VERSION "Powertrain_CAN_v1.0"

NS_ :

BS_:

BU_: SIL_TEST_CTRL ENGINE_CTRL TRANSMISSION_CTRL CHASSIS_GW DOMAIN_GW_ROUTER Vector__XXX

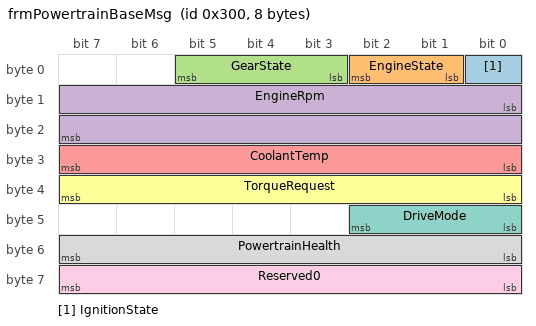
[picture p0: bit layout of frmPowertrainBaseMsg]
BO_ 768 frmPowertrainBaseMsg: 8 ENGINE_CTRL
 SG_ IgnitionState   : 0|1@1+ (1,0) [0|1] "" SIL_TEST_CTRL,CHASSIS_GW
 SG_ EngineState     : 1|2@1+ (1,0) [0|3] "" SIL_TEST_CTRL,CHASSIS_GW
 SG_ GearState       : 3|3@1+ (1,0) [0|7] "" SIL_TEST_CTRL,CHASSIS_GW
 SG_ EngineRpm       : 8|16@1+ (1,0) [0|65535] "rpm" CHASSIS_GW,DOMAIN_GW_ROUTER
 SG_ CoolantTemp     : 24|8@1+ (1,0) [0|255] "degC" DOMAIN_GW_ROUTER
 SG_ TorqueRequest   : 32|8@1+ (1,0) [0|255] "Nm" DOMAIN_GW_ROUTER
 SG_ DriveMode       : 40|3@1+ (1,0) [0|7] "" DOMAIN_GW_ROUTER
 SG_ PowertrainHealth: 48|8@1+ (1,0) [0|255] "" DOMAIN_GW_ROUTER
 SG_ Reserved0       : 56|8@1+ (1,0) [0|0] "" Vector__XXX

CM_ BO_ 768 "Comm_101 baseline powertrain aggregate message (Req_101~Req_102).";

BA_DEF_ BO_ "GenMsgCycleTime" INT 0 10000;
BA_DEF_DEF_ "GenMsgCycleTime" 0;
BA_ "GenMsgCycleTime" BO_ 768 100;

  0 "Off"
  1 "On" ;

  0 "Off"
  1 "Starting"
  2 "Running"
  3 "Fault" ;

  0 "Normal"
  1 "Eco"
  2 "Sport"
  3 "Snow"
  4 "Comfort"
  5 "Custom"
  6 "Reserved6"
  7 "Reserved7" ;
